# DMASS0_BCDMA_0_BCDMA_CRED register map
Vendor: Texas Instruments
Peripheral module from a debugger description file (folder am62A).
Registers are 32-bit, read-write, reset 0x0 unless marked. A register's access mark holds for its fields unless they carry their own. Offsets are as the file gives them; lines under a group give offsets from that group; [hi:lo] are bit positions; {n}, {i} and the like mark numbered series; 'fields as' and 'values as' point back to an identical list; <NAME> marks a mode.

## DMASS0_BCDMA_0_BCDMA_CRED
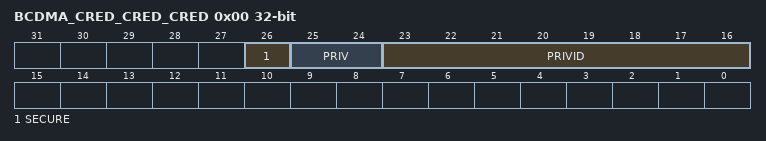
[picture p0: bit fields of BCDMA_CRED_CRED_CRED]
0x00 BCDMA_CRED_CRED_CRED — The Credentials Register provides credentials to be used when performing memory accesses using this flow.
  [26] SECURE — Secure attribute
  [25:24] PRIV — Privelege attribute
  [23:16] PRIVID — Privelege ID attribute
